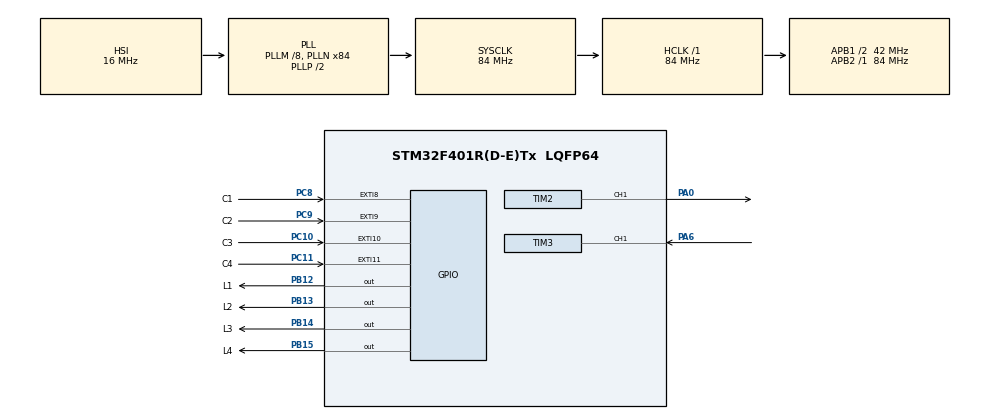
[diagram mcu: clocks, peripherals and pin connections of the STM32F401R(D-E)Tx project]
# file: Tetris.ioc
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Mcu.Family=STM32F4
Mcu.Name=STM32F401R(D-E)Tx
Mcu.Package=LQFP64
NVIC.EXTI15_10_IRQn=true\:2\:0\:true\:false\:true\:true
NVIC.EXTI9_5_IRQn=true\:2\:0\:true\:false\:true\:true
NVIC.PriorityGroup=NVIC_PRIORITYGROUP_4
NVIC.TIM2_IRQn=true\:1\:0\:true\:false\:true\:true
NVIC.TIM3_IRQn=true\:0\:0\:false\:false\:true\:true
PA0-WKUP.Signal=S_TIM2_CH1_ETR
PA6.Signal=S_TIM3_CH1
PB12.GPIO_Label=L1
PB12.GPIO_ModeDefaultOutputPP=GPIO_MODE_OUTPUT_OD
PB12.Signal=GPIO_Output
PB13.GPIO_Label=L2
PB13.GPIO_ModeDefaultOutputPP=GPIO_MODE_OUTPUT_OD
PB13.Signal=GPIO_Output
PB14.GPIO_Label=L3
PB14.GPIO_ModeDefaultOutputPP=GPIO_MODE_OUTPUT_OD
PB14.Signal=GPIO_Output
PB15.GPIO_Label=L4
PB15.GPIO_ModeDefaultOutputPP=GPIO_MODE_OUTPUT_OD
PB15.Signal=GPIO_Output
PC10.GPIO_Label=C3
PC10.GPIO_ModeDefaultEXTI=GPIO_MODE_IT_FALLING
PC10.GPIO_PuPd=GPIO_PULLUP
PC10.Signal=GPXTI10
PC11.GPIO_Label=C4
PC11.GPIO_ModeDefaultEXTI=GPIO_MODE_IT_FALLING
PC11.GPIO_PuPd=GPIO_PULLUP
PC11.Signal=GPXTI11
PC8.GPIO_Label=C1
PC8.GPIO_ModeDefaultEXTI=GPIO_MODE_IT_FALLING
PC8.GPIO_PuPd=GPIO_PULLUP
PC8.Signal=GPXTI8
PC9.GPIO_Label=C2
PC9.GPIO_ModeDefaultEXTI=GPIO_MODE_IT_FALLING
PC9.GPIO_PuPd=GPIO_PULLUP
PC9.Signal=GPXTI9
ProjectManager.HeapSize=0x200
ProjectManager.StackSize=0x400
ProjectManager.TargetToolchain=MDK-ARM V5
RCC.48MHZClocksFreq_Value=42000000
RCC.AHBFreq_Value=84000000
RCC.APB1CLKDivider=RCC_HCLK_DIV2
RCC.APB1Freq_Value=42000000
RCC.APB1TimFreq_Value=84000000
RCC.APB2Freq_Value=84000000
RCC.APB2TimFreq_Value=84000000
RCC.CortexFreq_Value=84000000
RCC.HCLKFreq_Value=84000000
RCC.HSE_VALUE=25000000
RCC.HSI_VALUE=16000000
RCC.LSE_VALUE=32768
RCC.PLLM=8
RCC.PLLN=84
RCC.SYSCLKFreq_VALUE=84000000
RCC.SYSCLKSource=RCC_SYSCLKSOURCE_PLLCLK
RCC.VCOOutputFreq_Value=168000000
SH.S_TIM2_CH1_ETR.0=TIM2_CH1,PWM Generation1 CH1
SH.S_TIM3_CH1.0=TIM3_CH1,Input_Capture1_from_TI1
TIM2.Channel-PWM\ Generation1\ CH1=TIM_CHANNEL_1
TIM2.CounterMode=TIM_COUNTERMODE_DOWN
TIM2.Period=65535
TIM2.Prescaler=15
TIM2.TIM_MasterOutputTrigger=TIM_TRGO_UPDATE
TIM3.Channel-Input_Capture1_from_TI1=TIM_CHANNEL_1
TIM3.ICPolarity_CH1=TIM_INPUTCHANNELPOLARITY_BOTHEDGE
TIM3.Period=65535
TIM3.Prescaler=15
VP_TIM2_VS_ClockSourceINT.Mode=Internal
VP_TIM3_VS_ClockSourceINT.Mode=Internal
board=Tetris

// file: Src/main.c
/**
  ******************************************************************************
  * File Name          : main.c
  * Description        : Main program body
  ******************************************************************************
  ** This notice applies to any and all portions of this file
  * that are not between comment pairs USER CODE BEGIN and
  * USER CODE END. Other portions of this file, whether
  * inserted by the user or by software development tools
  * are owned by their respective copyright owners.
  *
  * COPYRIGHT(c) 2017 STMicroelectronics
  *
  * Redistribution and use in source and binary forms, with or without modification,
  * are permitted provided that the following conditions are met:
  *   1. Redistributions of source code must retain the above copyright notice,
  *      this list of conditions and the following disclaimer.
  *   2. Redistributions in binary form must reproduce the above copyright notice,
  *      this list of conditions and the following disclaimer in the documentation
  *      and/or other materials provided with the distribution.
  *   3. Neither the name of STMicroelectronics nor the names of its contributors
  *      may be used to endorse or promote products derived from this software
  *      without specific prior written permission.
  *
  * THIS SOFTWARE IS PROVIDED BY THE COPYRIGHT HOLDERS AND CONTRIBUTORS "AS IS"
  * AND ANY EXPRESS OR IMPLIED WARRANTIES, INCLUDING, BUT NOT LIMITED TO, THE
  * IMPLIED WARRANTIES OF MERCHANTABILITY AND FITNESS FOR A PARTICULAR PURPOSE ARE
  * DISCLAIMED. IN NO EVENT SHALL THE COPYRIGHT HOLDER OR CONTRIBUTORS BE LIABLE
  * FOR ANY DIRECT, INDIRECT, INCIDENTAL, SPECIAL, EXEMPLARY, OR CONSEQUENTIAL
  * DAMAGES (INCLUDING, BUT NOT LIMITED TO, PROCUREMENT OF SUBSTITUTE GOODS OR
  * SERVICES; LOSS OF USE, DATA, OR PROFITS; OR BUSINESS INTERRUPTION) HOWEVER
  * CAUSED AND ON ANY THEORY OF LIABILITY, WHETHER IN CONTRACT, STRICT LIABILITY,
  * OR TORT (INCLUDING NEGLIGENCE OR OTHERWISE) ARISING IN ANY WAY OUT OF THE USE
  * OF THIS SOFTWARE, EVEN IF ADVISED OF THE POSSIBILITY OF SUCH DAMAGE.
  *
  ******************************************************************************
  */
#include "main.h"
#include "stm32f4xx_hal.h"
#include "tim.h"
#include "gpio.h"

//Pour débuger
void LCD_Begin(void);
void LCD_DrawPixel(int16_t x, int16_t y, uint16_t color);
void LCD_DrawLine(int16_t x1, int16_t y1, int16_t x2, int16_t y2, uint16_t color);
void LCD_DrawFastHLine(int16_t x, int16_t y, int16_t length, uint16_t color);
void LCD_DrawFastVLine(int16_t x, int16_t y, int16_t h, uint16_t color);
void LCD_DrawRect(int16_t x, int16_t y, int16_t w, int16_t h, uint16_t color);
void LCD_DrawRoundRect(int16_t x, int16_t y, int16_t w, int16_t h, int16_t r, uint16_t color);
void LCD_DrawCircleHelper( int16_t x0, int16_t y0, int16_t r, uint8_t cornername, uint16_t color);
void LCD_DrawCircle(int16_t x0, int16_t y0, int16_t r, uint16_t color);
void LCD_DrawChar(int16_t x, int16_t y, unsigned char c, uint16_t color, uint16_t bg, uint8_t size);
void LCD_FillCircle(int16_t x0, int16_t y0, int16_t r, uint16_t color);
void LCD_FillCircleHelper(int16_t x0, int16_t y0, int16_t r, uint8_t cornername, int16_t delta, uint16_t color);
void LCD_FillRect(int16_t x, int16_t y, int16_t w, int16_t h, uint16_t fillcolor);
void LCD_FillRoundRect(int16_t x, int16_t y, int16_t w, int16_t h, int16_t r, uint16_t color);
void LCD_FillScreen(uint16_t color);
void LCD_Flood(uint16_t color, uint32_t len);
void LCD_Reset(void);
void LCD_SetCursor(unsigned int x, unsigned int y);
void LCD_SetTextSize(uint8_t s);
void LCD_SetTextColor(uint16_t c, uint16_t b);
void LCD_SetTextWrap(uint8_t w) ;
void LCD_SetRotation(uint8_t x);
void LCD_SetAddrWindow(int x1, int y1, int x2, int y2);
void LCD_Printf(const char *fmt, ...);

/* USER CODE BEGIN PV */
/* Private variables ---------------------------------------------------------*/
char TIM3_update_flag = 0;
/* USER CODE END PV */

void SystemClock_Config(void);

/* USER CODE BEGIN PFP */
/* Private function prototypes -----------------------------------------------*/

/* USER CODE END PFP */

int main(void)
{

  /* USER CODE BEGIN 1 */
	extern float d1;  //pour débuger
  /* USER CODE END 1 */

  /* MCU Configuration----------------------------------------------------------*/

  /* Reset of all peripherals, Initializes the Flash interface and the Systick. */
  HAL_Init();

  /* Configure the system clock */
  SystemClock_Config();

  /* Initialize all configured peripherals */
  MX_GPIO_Init();
  MX_TIM2_Init();
  MX_TIM3_Init();

  /* USER CODE BEGIN 2 */

  //pour débuger
//	LCD_Begin();
//	LCD_FillScreen(1);
//	HAL_Delay(1000);
//	LCD_SetTextColor(65535, 1);
//	LCD_SetCursor(0,0);
//	LCD_SetTextSize(3);
//	LCD_Printf("Hello");

	HAL_TIM_PWM_Start(&htim2,TIM_CHANNEL_1);
	HAL_Delay(500);

/* USER CODE END 2 */

  /* Infinite loop */
  /* USER CODE BEGIN WHILE */
  while (1)
  {
		  //pour débuger
		if (TIM3_update_flag)
		{

			LCD_Printf("d: %f", d1);
			TIM3_update_flag = 0;
		}

  /* USER CODE END WHILE */

  }

}

/** System Clock Configuration
*/
void SystemClock_Config(void)
{

  RCC_OscInitTypeDef RCC_OscInitStruct;
  RCC_ClkInitTypeDef RCC_ClkInitStruct;

    /**Configure the main internal regulator output voltage
    */
  __HAL_RCC_PWR_CLK_ENABLE();

  __HAL_PWR_VOLTAGESCALING_CONFIG(PWR_REGULATOR_VOLTAGE_SCALE2);

    /**Initializes the CPU, AHB and APB busses clocks
    */
  RCC_OscInitStruct.OscillatorType = RCC_OSCILLATORTYPE_HSI;
  RCC_OscInitStruct.HSIState = RCC_HSI_ON;
  RCC_OscInitStruct.HSICalibrationValue = 16;
  RCC_OscInitStruct.PLL.PLLState = RCC_PLL_ON;
  RCC_OscInitStruct.PLL.PLLSource = RCC_PLLSOURCE_HSI;
  RCC_OscInitStruct.PLL.PLLM = 8;
  RCC_OscInitStruct.PLL.PLLN = 84;
  RCC_OscInitStruct.PLL.PLLP = RCC_PLLP_DIV2;
  RCC_OscInitStruct.PLL.PLLQ = 4;
  if (HAL_RCC_OscConfig(&RCC_OscInitStruct) != HAL_OK)
  {
    _Error_Handler(__FILE__, __LINE__);
  }

    /**Initializes the CPU, AHB and APB busses clocks
    */
  RCC_ClkInitStruct.ClockType = RCC_CLOCKTYPE_HCLK|RCC_CLOCKTYPE_SYSCLK
                              |RCC_CLOCKTYPE_PCLK1|RCC_CLOCKTYPE_PCLK2;
  RCC_ClkInitStruct.SYSCLKSource = RCC_SYSCLKSOURCE_PLLCLK;
  RCC_ClkInitStruct.AHBCLKDivider = RCC_SYSCLK_DIV1;
  RCC_ClkInitStruct.APB1CLKDivider = RCC_HCLK_DIV2;
  RCC_ClkInitStruct.APB2CLKDivider = RCC_HCLK_DIV1;

  if (HAL_RCC_ClockConfig(&RCC_ClkInitStruct, FLASH_LATENCY_2) != HAL_OK)
  {
    _Error_Handler(__FILE__, __LINE__);
  }

    /**Configure the Systick interrupt time
    */
  HAL_SYSTICK_Config(HAL_RCC_GetHCLKFreq()/1000);

    /**Configure the Systick
    */
  HAL_SYSTICK_CLKSourceConfig(SYSTICK_CLKSOURCE_HCLK);

  /* SysTick_IRQn interrupt configuration */
  HAL_NVIC_SetPriority(SysTick_IRQn, 0, 0);
}

void _Error_Handler(char * file, int line)
{
  while(1)
  {
  }
}

/************************ (C) COPYRIGHT STMicroelectronics *****END OF FILE****/
